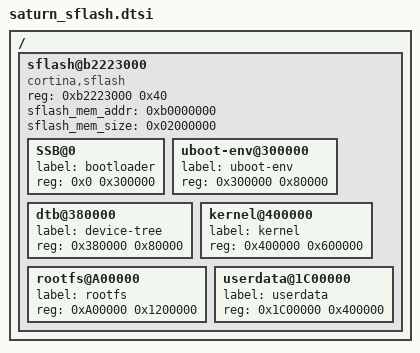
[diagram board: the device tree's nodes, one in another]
/*
 * Copyright (c) 2015-2017, Cortina Access. All rights reserved.
 *
 * Redistribution and use in source and binary forms, with or without
 * modification, are permitted provided that the following conditions are met:
 *
 * Redistributions of source code must retain the above copyright notice, this
 * list of conditions and the following disclaimer.
 *
 * Redistributions in binary form must reproduce the above copyright notice,
 * this list of conditions and the following disclaimer in the documentation
 * and/or other materials provided with the distribution.
 *
 * THIS SOFTWARE IS PROVIDED BY THE COPYRIGHT HOLDERS AND CONTRIBUTORS "AS IS"
 * AND ANY EXPRESS OR IMPLIED WARRANTIES, INCLUDING, BUT NOT LIMITED TO, THE
 * IMPLIED WARRANTIES OF MERCHANTABILITY AND FITNESS FOR A PARTICULAR PURPOSE
 * ARE DISCLAIMED. IN NO EVENT SHALL THE COPYRIGHT HOLDER OR CONTRIBUTORS BE
 * LIABLE FOR ANY DIRECT, INDIRECT, INCIDENTAL, SPECIAL, EXEMPLARY, OR
 * CONSEQUENTIAL DAMAGES (INCLUDING, BUT NOT LIMITED TO, PROCUREMENT OF
 * SUBSTITUTE GOODS OR SERVICES; LOSS OF USE, DATA, OR PROFITS; OR BUSINESS
 * INTERRUPTION) HOWEVER CAUSED AND ON ANY THEORY OF LIABILITY, WHETHER IN
 * CONTRACT, STRICT LIABILITY, OR TORT (INCLUDING NEGLIGENCE OR OTHERWISE)
 * ARISING IN ANY WAY OUT OF THE USE OF THIS SOFTWARE, EVEN IF ADVISED OF THE
 * POSSIBILITY OF SUCH DAMAGE.
 */

/ {
	sflash@b2223000 {
		#address-cells = <1>;
		#size-cells = <1>;
		compatible = "cortina,sflash";
		reg = <0xb2223000 0x40>;
		sflash_mem_addr = <0xb0000000>;
		sflash_mem_size = <0x02000000>;

		SSB@0 {
			label = "bootloader";
			reg = <0x0 0x300000>;
		};

		uboot-env@300000 {
			label = "uboot-env";
			reg = <0x300000 0x80000>;
		};

		dtb@380000 {
			label = "device-tree";
			reg = <0x380000 0x80000>;
		};

		kernel@400000 {
			label = "kernel";
			reg = <0x400000 0x600000>;
		};

		rootfs@A00000 {
			label = "rootfs";
			reg = <0xA00000 0x1200000>;
		};

		userdata@1C00000 {
			label = "userdata";
			reg = <0x1C00000 0x400000>;
		};

	};
};
